# FE310 register map
Vendor: SiFive; Series: Freedom Everywhere; File version: v19p05
CPU: E31 rv32imac, little endian, no MPU, no FPU, vendor SysTick, 1 interrupt priority bits
Registers are 32-bit, read-write, reset 0x0 unless marked. A register's access mark holds for its fields unless they carry their own. Offsets are from the block's base; [hi:lo] are bit positions; {n}, {i} and the like mark numbered series.

## BACKUP — Backup Registers.
Base 0x10000080
{0x0+4i} Backup[{i}] (i=0..31)

## RTC — Real-Time Clock.
Base 0x10000040
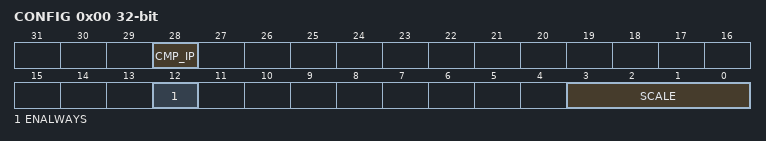
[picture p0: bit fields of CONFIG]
0x00 CONFIG — RTC Configuration Register.
  [28] CMP_IP, [12] ENALWAYS, [3:0] SCALE
0x08 LO — RTC Count Register Low.
0x0C HI — RTC Count Register High.
  [15:0] CNT
0x10 SCALE_COUNT — RTC Scaled Counter Register.
0x20 COMPARE — RTC Compare Register.

## PMU — Power Management Unit.
Base 0x10000100
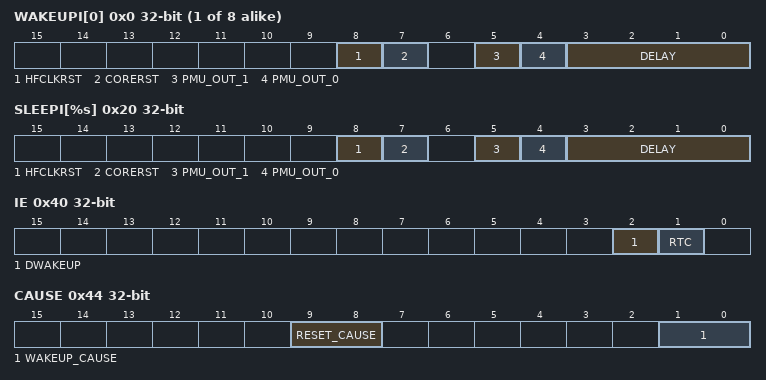
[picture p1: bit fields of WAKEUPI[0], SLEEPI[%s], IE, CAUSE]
{0x0+4i} WAKEUPI[{i}] (i=0..7) — Wakeup program instructions.
  [8] HFCLKRST, [7] CORERST, [5] PMU_OUT_1, [4] PMU_OUT_0, [3:0] DELAY
0x20 SLEEPI[%s] — Sleep program instructions.
  [8] HFCLKRST, [7] CORERST, [5] PMU_OUT_1, [4] PMU_OUT_0, [3:0] DELAY
0x40 IE — PMU interrupt enables.
  [2] DWAKEUP, [1] RTC
0x44 CAUSE — PMU wakeup cause.
  [9:8] RESET_CAUSE
    1=External reset; 2=Watchdog timer reset
  [1:0] WAKEUP_CAUSE
    0=Reset; 1=RTC (RTC Wakeup.); 2=DWakeup (Digital input wakeup.)
0x48 SLEEP — Initiate sleep sequence.
0x4C KEY — PMU key register.

## PRCI — Power, Reset, Clock, Interrupt.
Base 0x10008000
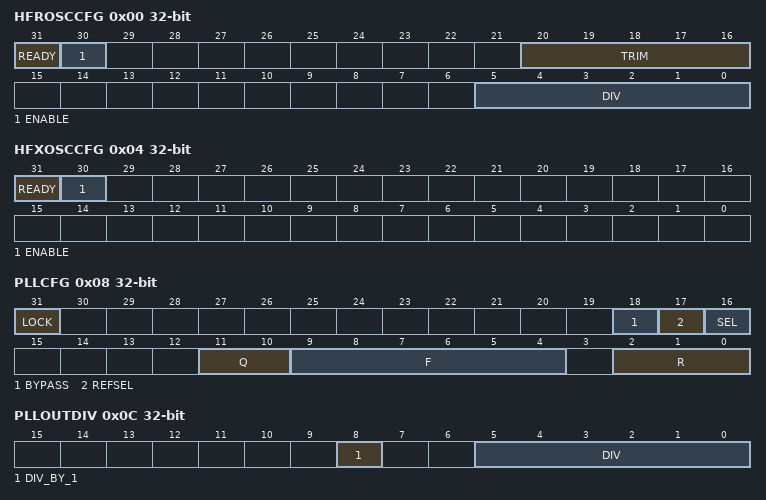
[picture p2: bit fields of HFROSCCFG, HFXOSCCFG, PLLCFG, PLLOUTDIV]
0x00 HFROSCCFG — HF Ring Oscillator Configuration Register.
  [31] READY, [30] ENABLE, [20:16] TRIM, [5:0] DIV
0x04 HFXOSCCFG — HF Crystal Oscillator Configuration Register.
  [31] READY, [30] ENABLE
0x08 PLLCFG — PLL Configuration Register.
  [31] LOCK
  [18] BYPASS
  [17] REFSEL
    1=Crystal OScillator; 0=Internal Oscillator
  [16] SEL
    0=Internal (The HFROSCCLK directly drives HFCLK.); 1=PLL (Drive the final HFCLK with PLL output, bypassed or otherwise.)
  [11:10] Q
  [9:4] F
  [2:0] R
0x0C PLLOUTDIV — PLL Output Divider Register.
  [8] DIV_BY_1, [5:0] DIV

## GPIO0 — General purpose input/output controller.
Base 0x10012000
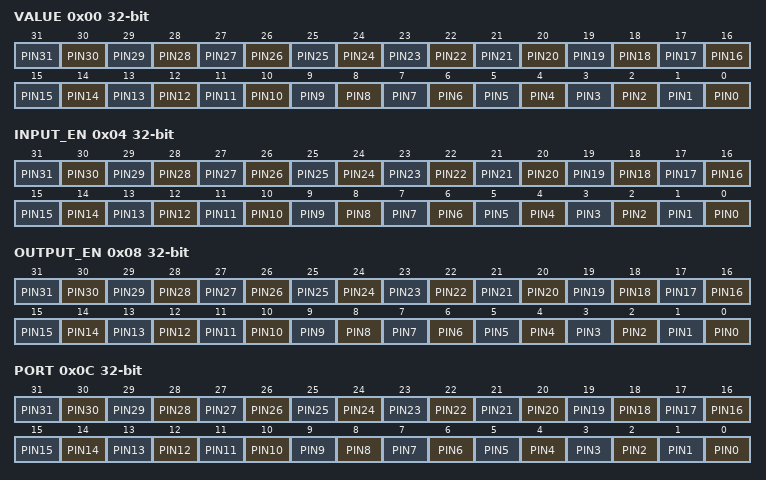
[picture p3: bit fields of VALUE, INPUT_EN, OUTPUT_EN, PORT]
0x00 VALUE — Pin value.
  [n] PIN{n} (n=0..31)
0x04 INPUT_EN — Pin input enable.
  [n] PIN{n} (n=0..31)
0x08 OUTPUT_EN — Pin output enable.
  [n] PIN{n} (n=0..31)
0x0C PORT — Output port value.
  [n] PIN{n} (n=0..31)
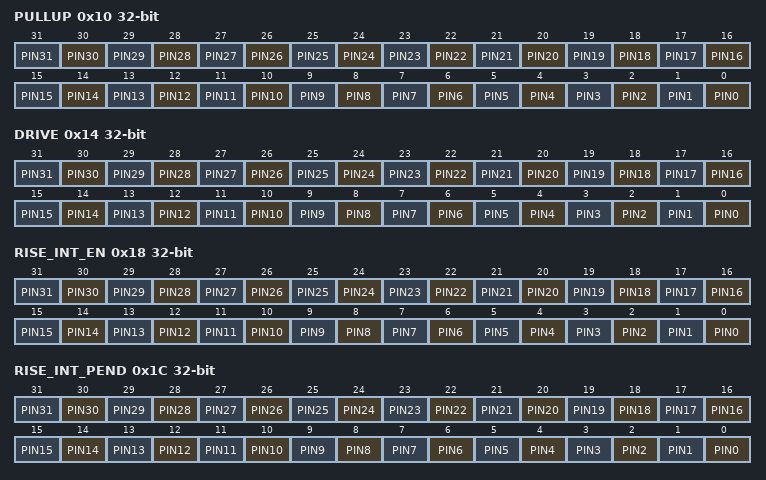
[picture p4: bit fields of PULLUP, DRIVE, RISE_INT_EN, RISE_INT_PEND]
0x10 PULLUP — Internal Pull-Up enable.
  [n] PIN{n} (n=0..31)
0x14 DRIVE — Drive Strength.
  [n] PIN{n} (n=0..31)
0x18 RISE_INT_EN — Rise interrupt enable.
  [n] PIN{n} (n=0..31)
0x1C RISE_INT_PEND — Rise interrupt pending.
  [n] PIN{n} (n=0..31)
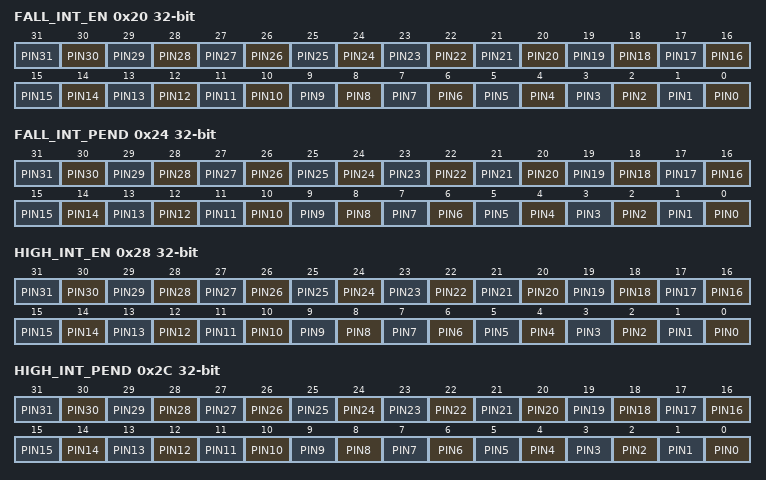
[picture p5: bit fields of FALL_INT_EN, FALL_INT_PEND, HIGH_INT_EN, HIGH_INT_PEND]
0x20 FALL_INT_EN — Fall interrupt enable.
  [n] PIN{n} (n=0..31)
0x24 FALL_INT_PEND — Fall interrupt pending.
  [n] PIN{n} (n=0..31)
0x28 HIGH_INT_EN — High interrupt enable.
  [n] PIN{n} (n=0..31)
0x2C HIGH_INT_PEND — High interrupt pending.
  [n] PIN{n} (n=0..31)
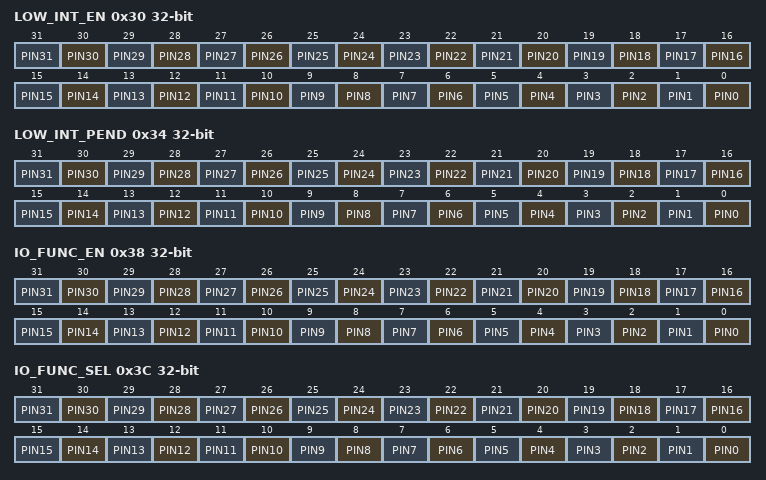
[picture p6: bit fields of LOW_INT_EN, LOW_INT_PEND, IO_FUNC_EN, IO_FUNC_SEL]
0x30 LOW_INT_EN — Low interrupt enable.
  [n] PIN{n} (n=0..31)
0x34 LOW_INT_PEND — Low interrupt pending.
  [n] PIN{n} (n=0..31)
0x38 IO_FUNC_EN — HW I/O function enable.
  [n] PIN{n} (n=0..31)
0x3C IO_FUNC_SEL — HW I/O function select.
  [n] PIN{n} (n=0..31)
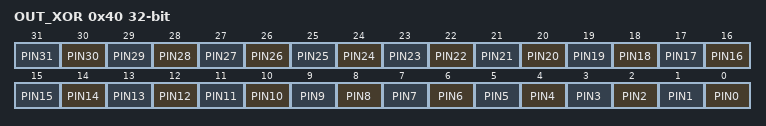
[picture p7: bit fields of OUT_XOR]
0x40 OUT_XOR — Output XOR (invert).
  [n] PIN{n} (n=0..31)

## UART0 — Universal Asynchronous Receiver/Transmitter.
Base 0x10013000
Same registers: UART1 0x10023000
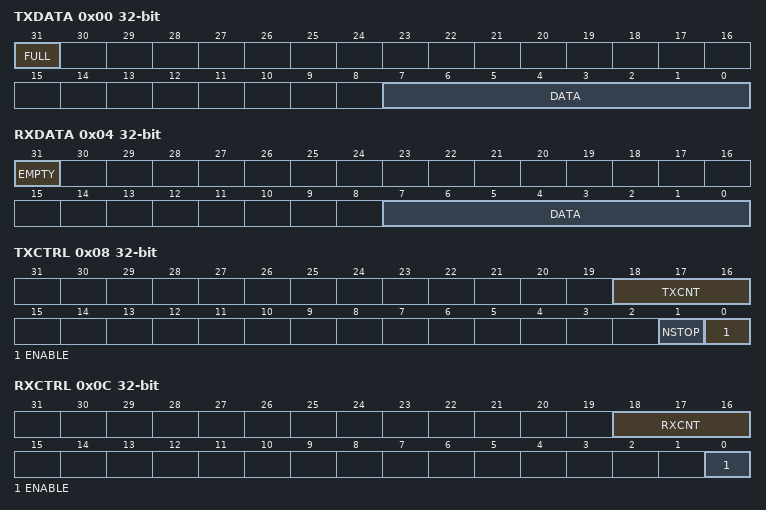
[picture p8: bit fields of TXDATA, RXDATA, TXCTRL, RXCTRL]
0x00 TXDATA — Transmit Data Register.
  [31] FULL, [7:0] DATA
0x04 RXDATA ro — Receive Data Register.
  [31] EMPTY, [7:0] DATA
0x08 TXCTRL — Transmit Control Register.
  [18:16] TXCNT, [1] NSTOP, [0] ENABLE
0x0C RXCTRL — Receive Control Register.
  [18:16] RXCNT, [0] ENABLE
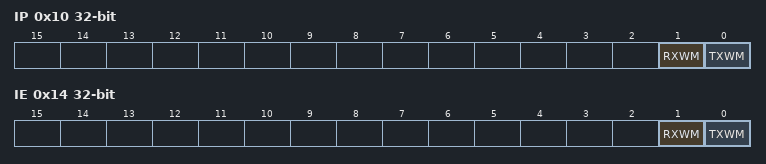
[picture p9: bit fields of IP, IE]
0x10 IP — Interrupt Pending Register.
  [1] RXWM, [0] TXWM
0x14 IE — Interrupt Enable Register.
  [1] RXWM, [0] TXWM
0x18 DIV — Baud Rate Divisor Register (BAUD = Fin / (DIV + 1)).
  [15:0] DIV

## QSPI0 — Quad Serial Peripheral Interface.
Base 0x10014000
Same registers: SPI1 0x10024000, SPI2 0x10034000
0x00 SCKDIV — Serial Clock Divisor Register.
  [11:0] SCALE
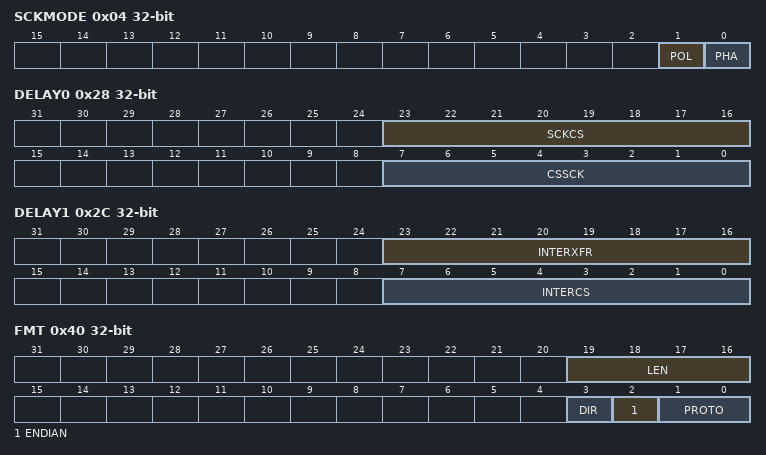
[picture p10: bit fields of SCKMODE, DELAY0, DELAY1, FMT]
0x04 SCKMODE — Serial Clock Mode Register.
  [1] POL — Serial Clock Polarity
    0=Inactive state of SCK is logical 0; 1=Inactive state of SCK is logical 1
  [0] PHA — Serial Clock Phase
    0=Data is sampled on the leading edge of SCK and shifted on the trailing edge of SCK; 1=Data is shifted on the leading edge of SCK and sampled on the trailing edge of SCK
0x10 CSID — Chip Select ID Register.
0x14 CSDEF — Chip Select Default Register.
0x18 CSMODE — Chip Select Mode Register.
  [1:0] MODE
    0=AUTO (Assert/de-assert CS at the beginning/end of each frame.); 2=HOLD (Keep CS continuously asserted after the initial frame.); 3=OFF (Disable hardware control of the CS pin.)
0x28 DELAY0 — Delay Control Register 0.
  [23:16] SCKCS, [7:0] CSSCK
0x2C DELAY1 — Delay Control Register 1.
  [23:16] INTERXFR, [7:0] INTERCS
0x40 FMT — Frame Format Register.
  [19:16] LEN
  [3] DIR
    0=RX (For dual and quad protocols, the DQ pins are tri-stated. For the single protocol, the DQ0 pin is driven with the transmit data as normal.); 1=TX (The receive FIFO is not populated.)
  [2] ENDIAN
    0=MSB_First (Tansmit most-significant bit first.); 1=LSB_First (Transmit least-significant bit first.)
  [1:0] PROTO
    0=Single (Data Pins: DQ0 (MOSI), DQ1 (MISO).); 1=Dual (Data Pins: DQ0, DQ1.); 2=Quad (Data Pins: DQ0, DQ1, DQ2, DQ3.)
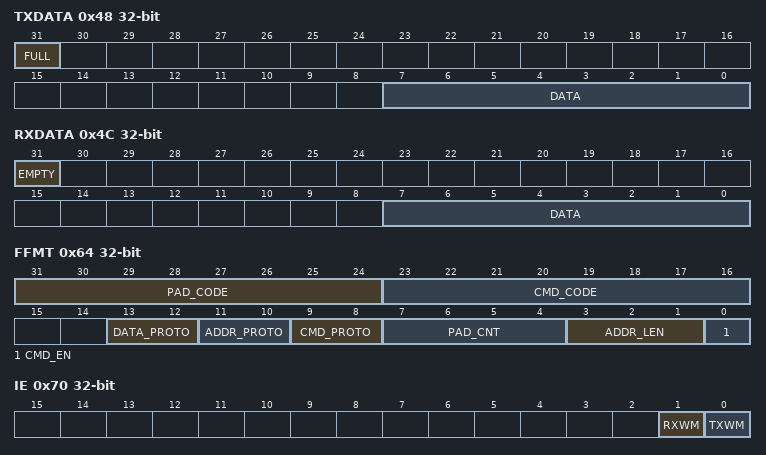
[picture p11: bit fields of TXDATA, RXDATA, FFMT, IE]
0x48 TXDATA — Transmit Data Register.
  [31] FULL, [7:0] DATA
0x4C RXDATA — Receive Data Register.
  [31] EMPTY, [7:0] DATA
0x50 TXMARK — Transmit Watermark Register.
  [2:0] TXMARK
0x54 RXMARK — Receive Watermark Register.
  [2:0] RXMARK
0x60 FCTRL — SPI Flash Interface Control Register.
  [0] ENABLE
0x64 FFMT — SPI Flash Instruction Format Register.
  [31:24] PAD_CODE, [23:16] CMD_CODE, [13:12] DATA_PROTO, [11:10] ADDR_PROTO, [9:8] CMD_PROTO, [7:4] PAD_CNT, [3:1] ADDR_LEN, [0] CMD_EN
0x70 IE — SPI Interrupt Enable Register.
  [1] RXWM, [0] TXWM
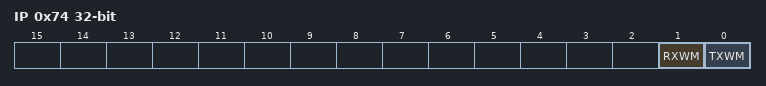
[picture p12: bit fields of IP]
0x74 IP — SPI Interrupt Pending Register.
  [1] RXWM, [0] TXWM

## PWM0 — Pulse-Width Modulation.
Base 0x10015000
Same registers: PWM1 0x10025000, PWM2 0x10035000
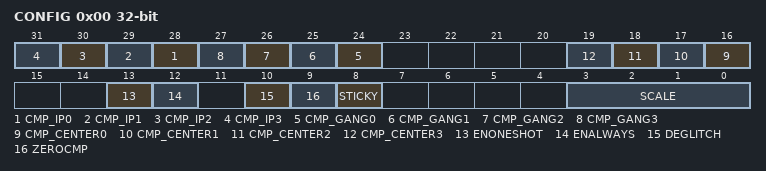
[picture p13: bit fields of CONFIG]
0x00 CONFIG — PWM Configuration Register.
  [n+28] CMP_IP{n} (n=0..3), [n+24] CMP_GANG{n} (n=0..3), [n+16] CMP_CENTER{n} (n=0..3), [13] ENONESHOT, [12] ENALWAYS, [10] DEGLITCH, [9] ZEROCMP, [8] STICKY, [3:0] SCALE
0x08 COUNT — PWM Count Register.
  [30:0] CNT
0x10 SCALE_COUNT — PWM Scaled Counter Register.
  [15:0] CNT
{0x20+4i} COMPARE{i} (i=0..3) — PWM Compare Register.
  [15:0] COMPARE

## I2C0 — Inter-Integrated Circuit.
Base 0x10016000
0x00 PRESCAL_LO — I2C Prescaler Low Register.
  [7:0] PRESCAL_LO
0x04 PRESCAL_HI — I2C Prescaler High Register.
  [7:0] PRESCAL_HI
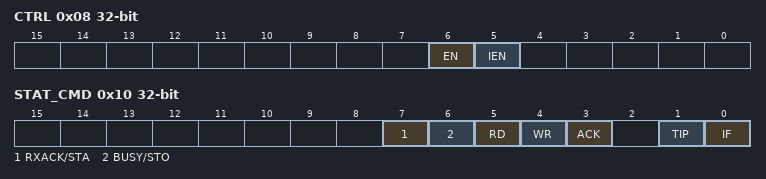
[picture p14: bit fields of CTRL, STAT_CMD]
0x08 CTRL — I2C Control Register.
  [6] EN, [5] IEN
0x0C DATA — I2C Data Register.
  [7:0] DATA
0x10 STAT_CMD — I2C Status Command Register.
  [7] RXACK/STA, [6] BUSY/STO, [5] RD, [4] WR, [3] ACK, [1] TIP, [0] IF
